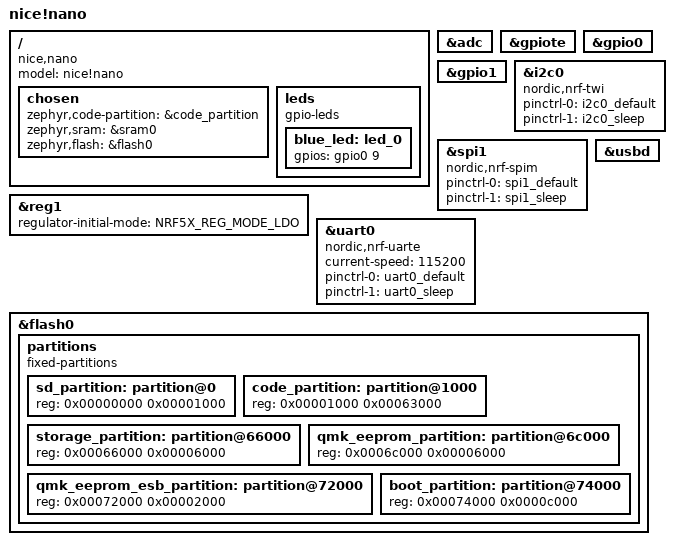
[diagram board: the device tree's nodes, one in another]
/*
 * Copyright (c) 2021 The ZMK Contributors
 *
 * SPDX-License-Identifier: MIT
 */

/dts-v1/;

#include <nordic/nrf52833_qdaa.dtsi>
#include <common/nordic/nrf52833_uf2_boot_mode.dtsi>

#include "nice_nano_k-pinctrl.dtsi"
// #include "arduino_pro_micro_pins.dtsi"


/ {
    model = "nice!nano";
    compatible = "nice,nano";

    chosen {
        zephyr,code-partition = &code_partition;
        zephyr,sram = &sram0;
        zephyr,flash = &flash0;
    };

    leds {
        compatible = "gpio-leds";
        blue_led: led_0 {
            gpios = <&gpio0 9 GPIO_ACTIVE_HIGH>;
        };
    };
};

&reg1 {
    regulator-initial-mode = <NRF5X_REG_MODE_LDO>;
};

&adc {
    status = "okay";
};

&gpiote {
    status = "okay";
};

&gpio0 {
    status = "okay";
};

&gpio1 {
    status = "okay";
};

&i2c0 {
    compatible = "nordic,nrf-twi";
    pinctrl-0 = <&i2c0_default>;
    pinctrl-1 = <&i2c0_sleep>;
    pinctrl-names = "default", "sleep";
};

&spi1 {
    compatible = "nordic,nrf-spim";
    pinctrl-0 = <&spi1_default>;
    pinctrl-1 = <&spi1_sleep>;
    pinctrl-names = "default", "sleep";
};

&uart0 {
    compatible = "nordic,nrf-uarte";
    current-speed = <115200>;
    pinctrl-0 = <&uart0_default>;
    pinctrl-1 = <&uart0_sleep>;
    pinctrl-names = "default", "sleep";
};

zephyr_udc0: &usbd {
    status = "okay";
};


&flash0 {
    /*
     * For more information, see:
     * http://docs.zephyrproject.org/latest/devices/dts/flash_partitions.html
     */
    partitions {
        compatible = "fixed-partitions";
        #address-cells = <1>;
        #size-cells = <1>;

        sd_partition: partition@0 {
            reg = <0x00000000 0x00001000>;//System reserved
        };
        // qmkcode_partition: partition@1000 {
        //     reg = <0x00001000 0x00017000>;//92K （4k-96KB）
        // };
        code_partition: partition@1000 {
            reg = <0x00001000 0x00063000>; //396K (4k-400k)
        };

        // code_partition: partition@18000 {
        //     reg = <0x00018000 0x0004e000>; //396K (96K-400k)
        // };

        storage_partition: partition@66000 {
            reg = <0x00066000 0x00006000>;//24K (408K-432K)
        };

        qmk_eeprom_partition: partition@6c000 {
            reg = <0x0006c000 0x00006000>;//(432K-456k)
        };

        qmk_eeprom_esb_partition: partition@72000 {
            reg = <0x00072000 0x00002000>;//(456K-464k)
        };

        boot_partition: partition@74000 {//464k-512k 48k
            reg = <0x00074000 0x0000c000>;
        };
    };
};
